AUTOSAR XML (schema 4-2-2)
package /UAES/ASW
  swc implementation Implementation: programming-language=C, sw-version=1.214.1, used-code-generator=Embedded Coder 7.1 (R2018b) 24-May-2018, vendor-id=0, behavior=InternalBehavior
    code-descriptors:
      code Code
        artifact-descriptors:
          short-label=Win_ComCnvRx_c, category=SWSRC
          short-label=Win_ComCnvRx_h, category=SWHDR
          short-label=rtwtypes_h, category=SWHDR
    resource consumption RsrcCons_Win_ComCnvRx
package /UAES/ASW/SwComponentTypes
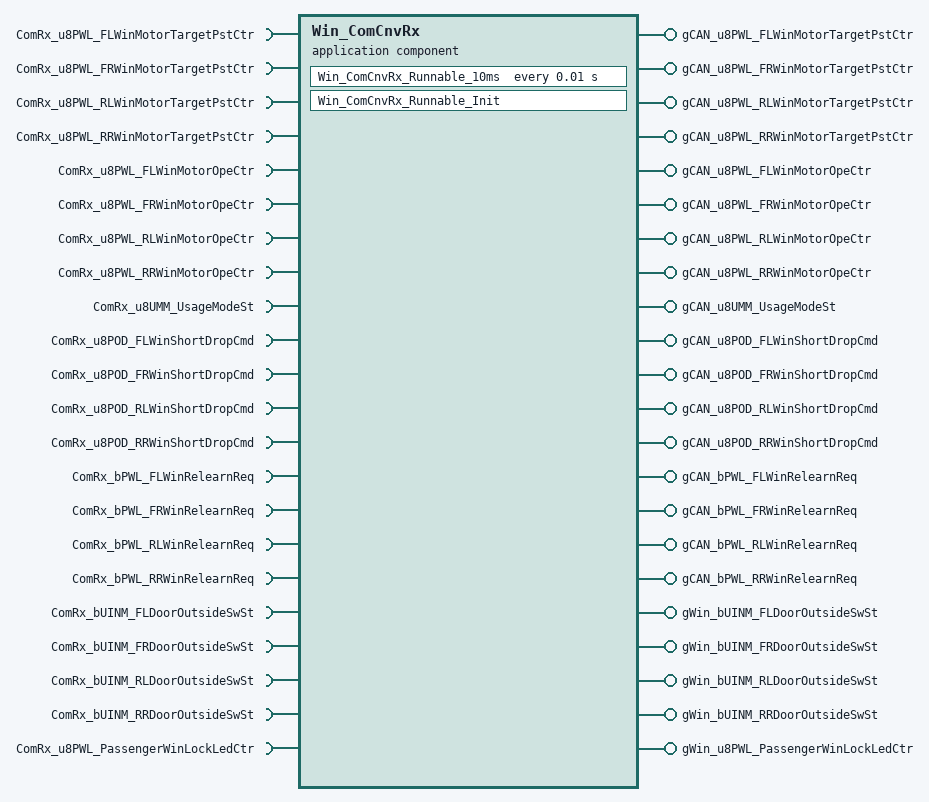
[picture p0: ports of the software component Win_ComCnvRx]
  application sw component type Win_ComCnvRx
    22 x require port:
      ComRx_u8PWL_FLWinMotorTargetPstCtr: nonqueued-receiver-com-spec{data-element=ComRx_u8PWL_FLWinMotorTargetPstCtr/Val, init-value=0}, required-interface=ComRx_u8PWL_FLWinMotorTargetPstCtr
      ComRx_u8PWL_FRWinMotorTargetPstCtr: nonqueued-receiver-com-spec{data-element=ComRx_u8PWL_FRWinMotorTargetPstCtr/Val, init-value=0}, required-interface=ComRx_u8PWL_FRWinMotorTargetPstCtr
      ComRx_u8PWL_RLWinMotorTargetPstCtr: nonqueued-receiver-com-spec{data-element=ComRx_u8PWL_RLWinMotorTargetPstCtr/Val, init-value=0}, required-interface=ComRx_u8PWL_RLWinMotorTargetPstCtr
      ComRx_u8PWL_RRWinMotorTargetPstCtr: nonqueued-receiver-com-spec{data-element=ComRx_u8PWL_RRWinMotorTargetPstCtr/Val, init-value=0}, required-interface=ComRx_u8PWL_RRWinMotorTargetPstCtr
      ComRx_u8PWL_FLWinMotorOpeCtr: nonqueued-receiver-com-spec{data-element=ComRx_u8PWL_FLWinMotorOpeCtr/Val, init-value=0}, required-interface=ComRx_u8PWL_FLWinMotorOpeCtr
      ComRx_u8PWL_FRWinMotorOpeCtr: nonqueued-receiver-com-spec{data-element=ComRx_u8PWL_FRWinMotorOpeCtr/Val, init-value=0}, required-interface=ComRx_u8PWL_FRWinMotorOpeCtr
      ComRx_u8PWL_RLWinMotorOpeCtr: nonqueued-receiver-com-spec{data-element=ComRx_u8PWL_RLWinMotorOpeCtr/Val, init-value=0}, required-interface=ComRx_u8PWL_RLWinMotorOpeCtr
      ComRx_u8PWL_RRWinMotorOpeCtr: nonqueued-receiver-com-spec{data-element=ComRx_u8PWL_RRWinMotorOpeCtr/Val, init-value=0}, required-interface=ComRx_u8PWL_RRWinMotorOpeCtr
      ComRx_u8UMM_UsageModeSt: nonqueued-receiver-com-spec{data-element=ComRx_u8UMM_UsageModeSt/Val, init-value=0}, required-interface=ComRx_u8UMM_UsageModeSt
      ComRx_u8POD_FLWinShortDropCmd: nonqueued-receiver-com-spec{data-element=ComRx_u8POD_FLWinShortDropCmd/Val, init-value=0}, required-interface=ComRx_u8POD_FLWinShortDropCmd
      ComRx_u8POD_FRWinShortDropCmd: nonqueued-receiver-com-spec{data-element=ComRx_u8POD_FRWinShortDropCmd/Val, init-value=0}, required-interface=ComRx_u8POD_FRWinShortDropCmd
      ComRx_u8POD_RLWinShortDropCmd: nonqueued-receiver-com-spec{data-element=ComRx_u8POD_RLWinShortDropCmd/Val, init-value=0}, required-interface=ComRx_u8POD_RLWinShortDropCmd
      ComRx_u8POD_RRWinShortDropCmd: nonqueued-receiver-com-spec{data-element=ComRx_u8POD_RRWinShortDropCmd/Val, init-value=0}, required-interface=ComRx_u8POD_RRWinShortDropCmd
      ComRx_bPWL_FLWinRelearnReq: nonqueued-receiver-com-spec{data-element=ComRx_bPWL_FLWinRelearnReq/Val, init-value=0}, required-interface=ComRx_bPWL_FLWinRelearnReq
      ComRx_bPWL_FRWinRelearnReq: nonqueued-receiver-com-spec{data-element=ComRx_bPWL_FRWinRelearnReq/Val, init-value=0}, required-interface=ComRx_bPWL_FRWinRelearnReq
      ComRx_bPWL_RLWinRelearnReq: nonqueued-receiver-com-spec{data-element=ComRx_bPWL_RLWinRelearnReq/Val, init-value=0}, required-interface=ComRx_bPWL_RLWinRelearnReq
      ComRx_bPWL_RRWinRelearnReq: nonqueued-receiver-com-spec{data-element=ComRx_bPWL_RRWinRelearnReq/Val, init-value=0}, required-interface=ComRx_bPWL_RRWinRelearnReq
      ComRx_bUINM_FLDoorOutsideSwSt: nonqueued-receiver-com-spec{data-element=ComRx_bUINM_FLDoorOutsideSwSt/Val, init-value=0}, required-interface=ComRx_bUINM_FLDoorOutsideSwSt
      ComRx_bUINM_FRDoorOutsideSwSt: nonqueued-receiver-com-spec{data-element=ComRx_bUINM_FRDoorOutsideSwSt/Val, init-value=0}, required-interface=ComRx_bUINM_FRDoorOutsideSwSt
      ComRx_bUINM_RLDoorOutsideSwSt: nonqueued-receiver-com-spec{data-element=ComRx_bUINM_RLDoorOutsideSwSt/Val, init-value=0}, required-interface=ComRx_bUINM_RLDoorOutsideSwSt
      ComRx_bUINM_RRDoorOutsideSwSt: nonqueued-receiver-com-spec{data-element=ComRx_bUINM_RRDoorOutsideSwSt/Val, init-value=0}, required-interface=ComRx_bUINM_RRDoorOutsideSwSt
      ComRx_u8PWL_PassengerWinLockLedCtr: nonqueued-receiver-com-spec{data-element=ComRx_u8PWL_PassengerWinLockLedCtr/Val, init-value=0}, required-interface=ComRx_u8PWL_PassengerWinLockLedCtr
    22 x provide port:
      gCAN_u8PWL_FLWinMotorTargetPstCtr: nonqueued-sender-com-spec{data-element=gCAN_u8PWL_FLWinMotorTargetPstCtr/Val, init-value=0}, provided-interface=gCAN_u8PWL_FLWinMotorTargetPstCtr
      gCAN_u8PWL_FRWinMotorTargetPstCtr: nonqueued-sender-com-spec{data-element=gCAN_u8PWL_FRWinMotorTargetPstCtr/Val, init-value=0}, provided-interface=gCAN_u8PWL_FRWinMotorTargetPstCtr
      gCAN_u8PWL_RLWinMotorTargetPstCtr: nonqueued-sender-com-spec{data-element=gCAN_u8PWL_RLWinMotorTargetPstCtr/Val, init-value=0}, provided-interface=gCAN_u8PWL_RLWinMotorTargetPstCtr
      gCAN_u8PWL_RRWinMotorTargetPstCtr: nonqueued-sender-com-spec{data-element=gCAN_u8PWL_RRWinMotorTargetPstCtr/Val, init-value=0}, provided-interface=gCAN_u8PWL_RRWinMotorTargetPstCtr
      gCAN_u8PWL_FLWinMotorOpeCtr: nonqueued-sender-com-spec{data-element=gCAN_u8PWL_FLWinMotorOpeCtr/Val, init-value=0}, provided-interface=gCAN_u8PWL_FLWinMotorOpeCtr
      gCAN_u8PWL_FRWinMotorOpeCtr: nonqueued-sender-com-spec{data-element=gCAN_u8PWL_FRWinMotorOpeCtr/Val, init-value=0}, provided-interface=gCAN_u8PWL_FRWinMotorOpeCtr
      gCAN_u8PWL_RLWinMotorOpeCtr: nonqueued-sender-com-spec{data-element=gCAN_u8PWL_RLWinMotorOpeCtr/Val, init-value=0}, provided-interface=gCAN_u8PWL_RLWinMotorOpeCtr
      gCAN_u8PWL_RRWinMotorOpeCtr: nonqueued-sender-com-spec{data-element=gCAN_u8PWL_RRWinMotorOpeCtr/Val, init-value=0}, provided-interface=gCAN_u8PWL_RRWinMotorOpeCtr
      gCAN_u8UMM_UsageModeSt: nonqueued-sender-com-spec{data-element=gCAN_u8UMM_UsageModeSt/Val, init-value=0}, provided-interface=gCAN_u8UMM_UsageModeSt
      gCAN_u8POD_FLWinShortDropCmd: nonqueued-sender-com-spec{data-element=gCAN_u8POD_FLWinShortDropCmd/Val, init-value=0}, provided-interface=gCAN_u8POD_FLWinShortDropCmd
      gCAN_u8POD_FRWinShortDropCmd: nonqueued-sender-com-spec{data-element=gCAN_u8POD_FRWinShortDropCmd/Val, init-value=0}, provided-interface=gCAN_u8POD_FRWinShortDropCmd
      gCAN_u8POD_RLWinShortDropCmd: nonqueued-sender-com-spec{data-element=gCAN_u8POD_RLWinShortDropCmd/Val, init-value=0}, provided-interface=gCAN_u8POD_RLWinShortDropCmd
      gCAN_u8POD_RRWinShortDropCmd: nonqueued-sender-com-spec{data-element=gCAN_u8POD_RRWinShortDropCmd/Val, init-value=0}, provided-interface=gCAN_u8POD_RRWinShortDropCmd
      gCAN_bPWL_FLWinRelearnReq: nonqueued-sender-com-spec{data-element=gCAN_bPWL_FLWinRelearnReq/Val, init-value=0}, provided-interface=gCAN_bPWL_FLWinRelearnReq
      gCAN_bPWL_FRWinRelearnReq: nonqueued-sender-com-spec{data-element=gCAN_bPWL_FRWinRelearnReq/Val, init-value=0}, provided-interface=gCAN_bPWL_FRWinRelearnReq
      gCAN_bPWL_RLWinRelearnReq: nonqueued-sender-com-spec{data-element=gCAN_bPWL_RLWinRelearnReq/Val, init-value=0}, provided-interface=gCAN_bPWL_RLWinRelearnReq
      gCAN_bPWL_RRWinRelearnReq: nonqueued-sender-com-spec{data-element=gCAN_bPWL_RRWinRelearnReq/Val, init-value=0}, provided-interface=gCAN_bPWL_RRWinRelearnReq
      gWin_bUINM_FLDoorOutsideSwSt: nonqueued-sender-com-spec{data-element=gWin_bUINM_FLDoorOutsideSwSt/Val, init-value=0}, provided-interface=gWin_bUINM_FLDoorOutsideSwSt
      gWin_bUINM_FRDoorOutsideSwSt: nonqueued-sender-com-spec{data-element=gWin_bUINM_FRDoorOutsideSwSt/Val, init-value=0}, provided-interface=gWin_bUINM_FRDoorOutsideSwSt
      gWin_bUINM_RLDoorOutsideSwSt: nonqueued-sender-com-spec{data-element=gWin_bUINM_RLDoorOutsideSwSt/Val, init-value=0}, provided-interface=gWin_bUINM_RLDoorOutsideSwSt
      gWin_bUINM_RRDoorOutsideSwSt: nonqueued-sender-com-spec{data-element=gWin_bUINM_RRDoorOutsideSwSt/Val, init-value=0}, provided-interface=gWin_bUINM_RRDoorOutsideSwSt
      gWin_u8PWL_PassengerWinLockLedCtr: nonqueued-sender-com-spec{data-element=gWin_u8PWL_PassengerWinLockLedCtr/Val, init-value=0}, provided-interface=gWin_u8PWL_PassengerWinLockLedCtr
    behavior InternalBehavior: handle-termination-and-restart=NO-SUPPORT
      init event Win_ComCnvRx_InitEvent: start-on-event=Win_ComCnvRx_Runnable_Init
      timing event TMT_Win_ComCnvRx_Runnable_10ms: start-on-event=Win_ComCnvRx_Runnable_10ms, period=0.01
      runnable Win_ComCnvRx_Runnable_Init
      runnable Win_ComCnvRx_Runnable_10ms
        data-receive-point-by-arguments:
          22 x access:
            IN_ComRx_bPWL_FLWinRelearnReq_Val: accessed-variable=ComRx_bPWL_FLWinRelearnReq.Val
            IN_ComRx_bPWL_FRWinRelearnReq_Val: accessed-variable=ComRx_bPWL_FRWinRelearnReq.Val
            IN_ComRx_bPWL_RLWinRelearnReq_Val: accessed-variable=ComRx_bPWL_RLWinRelearnReq.Val
            IN_ComRx_bPWL_RRWinRelearnReq_Val: accessed-variable=ComRx_bPWL_RRWinRelearnReq.Val
            IN_ComRx_bUINM_FLDoorOutsideSwSt_Val: accessed-variable=ComRx_bUINM_FLDoorOutsideSwSt.Val
            IN_ComRx_bUINM_FRDoorOutsideSwSt_Val: accessed-variable=ComRx_bUINM_FRDoorOutsideSwSt.Val
            IN_ComRx_bUINM_RLDoorOutsideSwSt_Val: accessed-variable=ComRx_bUINM_RLDoorOutsideSwSt.Val
            IN_ComRx_bUINM_RRDoorOutsideSwSt_Val: accessed-variable=ComRx_bUINM_RRDoorOutsideSwSt.Val
            IN_ComRx_u8POD_FLWinShortDropCmd_Val: accessed-variable=ComRx_u8POD_FLWinShortDropCmd.Val
            IN_ComRx_u8POD_FRWinShortDropCmd_Val: accessed-variable=ComRx_u8POD_FRWinShortDropCmd.Val
            IN_ComRx_u8POD_RLWinShortDropCmd_Val: accessed-variable=ComRx_u8POD_RLWinShortDropCmd.Val
            IN_ComRx_u8POD_RRWinShortDropCmd_Val: accessed-variable=ComRx_u8POD_RRWinShortDropCmd.Val
            IN_ComRx_u8PWL_FLWinMotorOpeCtr_Val: accessed-variable=ComRx_u8PWL_FLWinMotorOpeCtr.Val
            IN_ComRx_u8PWL_FLWinMotorTargetPstCtr_Val: accessed-variable=ComRx_u8PWL_FLWinMotorTargetPstCtr.Val
            IN_ComRx_u8PWL_FRWinMotorOpeCtr_Val: accessed-variable=ComRx_u8PWL_FRWinMotorOpeCtr.Val
            IN_ComRx_u8PWL_FRWinMotorTargetPstCtr_Val: accessed-variable=ComRx_u8PWL_FRWinMotorTargetPstCtr.Val
            IN_ComRx_u8PWL_PassengerWinLockLedCtr_Val: accessed-variable=ComRx_u8PWL_PassengerWinLockLedCtr.Val
            IN_ComRx_u8PWL_RLWinMotorOpeCtr_Val: accessed-variable=ComRx_u8PWL_RLWinMotorOpeCtr.Val
            IN_ComRx_u8PWL_RLWinMotorTargetPstCtr_Val: accessed-variable=ComRx_u8PWL_RLWinMotorTargetPstCtr.Val
            IN_ComRx_u8PWL_RRWinMotorOpeCtr_Val: accessed-variable=ComRx_u8PWL_RRWinMotorOpeCtr.Val
            IN_ComRx_u8PWL_RRWinMotorTargetPstCtr_Val: accessed-variable=ComRx_u8PWL_RRWinMotorTargetPstCtr.Val
            IN_ComRx_u8UMM_UsageModeSt_Val: accessed-variable=ComRx_u8UMM_UsageModeSt.Val
        data-send-points:
          22 x access:
            OUT_gCAN_u8PWL_FLWinMotorTargetPstCtr_Val: accessed-variable=gCAN_u8PWL_FLWinMotorTargetPstCtr.Val
            OUT_gCAN_u8PWL_FRWinMotorTargetPstCtr_Val: accessed-variable=gCAN_u8PWL_FRWinMotorTargetPstCtr.Val
            OUT_gCAN_u8PWL_RLWinMotorTargetPstCtr_Val: accessed-variable=gCAN_u8PWL_RLWinMotorTargetPstCtr.Val
            OUT_gCAN_u8PWL_RRWinMotorTargetPstCtr_Val: accessed-variable=gCAN_u8PWL_RRWinMotorTargetPstCtr.Val
            OUT_gCAN_u8PWL_FLWinMotorOpeCtr_Val: accessed-variable=gCAN_u8PWL_FLWinMotorOpeCtr.Val
            OUT_gCAN_u8PWL_FRWinMotorOpeCtr_Val: accessed-variable=gCAN_u8PWL_FRWinMotorOpeCtr.Val
            OUT_gCAN_u8PWL_RLWinMotorOpeCtr_Val: accessed-variable=gCAN_u8PWL_RLWinMotorOpeCtr.Val
            OUT_gCAN_u8PWL_RRWinMotorOpeCtr_Val: accessed-variable=gCAN_u8PWL_RRWinMotorOpeCtr.Val
            OUT_gCAN_u8UMM_UsageModeSt_Val: accessed-variable=gCAN_u8UMM_UsageModeSt.Val
            OUT_gCAN_u8POD_FLWinShortDropCmd_Val: accessed-variable=gCAN_u8POD_FLWinShortDropCmd.Val
            OUT_gCAN_u8POD_FRWinShortDropCmd_Val: accessed-variable=gCAN_u8POD_FRWinShortDropCmd.Val
            OUT_gCAN_u8POD_RLWinShortDropCmd_Val: accessed-variable=gCAN_u8POD_RLWinShortDropCmd.Val
            OUT_gCAN_u8POD_RRWinShortDropCmd_Val: accessed-variable=gCAN_u8POD_RRWinShortDropCmd.Val
            OUT_gCAN_bPWL_FLWinRelearnReq_Val: accessed-variable=gCAN_bPWL_FLWinRelearnReq.Val
            OUT_gCAN_bPWL_FRWinRelearnReq_Val: accessed-variable=gCAN_bPWL_FRWinRelearnReq.Val
            OUT_gCAN_bPWL_RLWinRelearnReq_Val: accessed-variable=gCAN_bPWL_RLWinRelearnReq.Val
            OUT_gCAN_bPWL_RRWinRelearnReq_Val: accessed-variable=gCAN_bPWL_RRWinRelearnReq.Val
            OUT_gWin_bUINM_FLDoorOutsideSwSt_Val: accessed-variable=gWin_bUINM_FLDoorOutsideSwSt.Val
            OUT_gWin_bUINM_FRDoorOutsideSwSt_Val: accessed-variable=gWin_bUINM_FRDoorOutsideSwSt.Val
            OUT_gWin_bUINM_RLDoorOutsideSwSt_Val: accessed-variable=gWin_bUINM_RLDoorOutsideSwSt.Val
            OUT_gWin_bUINM_RRDoorOutsideSwSt_Val: accessed-variable=gWin_bUINM_RRDoorOutsideSwSt.Val
            OUT_gWin_u8PWL_PassengerWinLockLedCtr_Val: accessed-variable=gWin_u8PWL_PassengerWinLockLedCtr.Val
package /UAES/ASW/PortInterfaces
  44 x sender receiver interface:
    ComRx_u8PWL_FLWinMotorTargetPstCtr
      data Val: category=VALUE, sw-calibration-access=READ-ONLY, type=uint8
    ComRx_u8PWL_FRWinMotorTargetPstCtr
      data Val: category=VALUE, sw-calibration-access=READ-ONLY, type=uint8
    ComRx_u8PWL_RLWinMotorTargetPstCtr
      data Val: category=VALUE, sw-calibration-access=READ-ONLY, type=uint8
    ComRx_u8PWL_RRWinMotorTargetPstCtr
      data Val: category=VALUE, sw-calibration-access=READ-ONLY, type=uint8
    ComRx_u8PWL_FLWinMotorOpeCtr
      data Val: category=VALUE, sw-calibration-access=READ-ONLY, type=uint8
    ComRx_u8PWL_FRWinMotorOpeCtr
      data Val: category=VALUE, sw-calibration-access=READ-ONLY, type=uint8
    ComRx_u8PWL_RLWinMotorOpeCtr
      data Val: category=VALUE, sw-calibration-access=READ-ONLY, type=uint8
    ComRx_u8PWL_RRWinMotorOpeCtr
      data Val: category=VALUE, sw-calibration-access=READ-ONLY, type=uint8
    ComRx_u8UMM_UsageModeSt
      data Val: category=VALUE, sw-calibration-access=READ-ONLY, type=uint8
    ComRx_u8POD_FLWinShortDropCmd
      data Val: category=VALUE, sw-calibration-access=READ-ONLY, type=uint8
    ComRx_u8POD_FRWinShortDropCmd
      data Val: category=VALUE, sw-calibration-access=READ-ONLY, type=uint8
    ComRx_u8POD_RLWinShortDropCmd
      data Val: category=VALUE, sw-calibration-access=READ-ONLY, type=uint8
    ComRx_u8POD_RRWinShortDropCmd
      data Val: category=VALUE, sw-calibration-access=READ-ONLY, type=uint8
    ComRx_bPWL_FLWinRelearnReq
      data Val: category=VALUE, sw-calibration-access=READ-ONLY, type=boolean
    ComRx_bPWL_FRWinRelearnReq
      data Val: category=VALUE, sw-calibration-access=READ-ONLY, type=boolean
    ComRx_bPWL_RLWinRelearnReq
      data Val: category=VALUE, sw-calibration-access=READ-ONLY, type=boolean
    ComRx_bPWL_RRWinRelearnReq
      data Val: category=VALUE, sw-calibration-access=READ-ONLY, type=boolean
    ComRx_bUINM_FLDoorOutsideSwSt
      data Val: category=VALUE, sw-calibration-access=READ-ONLY, type=boolean
    ComRx_bUINM_FRDoorOutsideSwSt
      data Val: category=VALUE, sw-calibration-access=READ-ONLY, type=boolean
    ComRx_bUINM_RLDoorOutsideSwSt
      data Val: category=VALUE, sw-calibration-access=READ-ONLY, type=boolean
    ComRx_bUINM_RRDoorOutsideSwSt
      data Val: category=VALUE, sw-calibration-access=READ-ONLY, type=boolean
    ComRx_u8PWL_PassengerWinLockLedCtr
      data Val: category=VALUE, sw-calibration-access=READ-ONLY, type=uint8
    gCAN_u8PWL_FLWinMotorTargetPstCtr
      data Val: category=VALUE, sw-calibration-access=READ-ONLY, type=uint8
    gCAN_u8PWL_FRWinMotorTargetPstCtr
      data Val: category=VALUE, sw-calibration-access=READ-ONLY, type=uint8
    gCAN_u8PWL_RLWinMotorTargetPstCtr
      data Val: category=VALUE, sw-calibration-access=READ-ONLY, type=uint8
    gCAN_u8PWL_RRWinMotorTargetPstCtr
      data Val: category=VALUE, sw-calibration-access=READ-ONLY, type=uint8
    gCAN_u8PWL_FLWinMotorOpeCtr
      data Val: category=VALUE, sw-calibration-access=READ-ONLY, type=uint8
    gCAN_u8PWL_FRWinMotorOpeCtr
      data Val: category=VALUE, sw-calibration-access=READ-ONLY, type=uint8
    gCAN_u8PWL_RLWinMotorOpeCtr
      data Val: category=VALUE, sw-calibration-access=READ-ONLY, type=uint8
    gCAN_u8PWL_RRWinMotorOpeCtr
      data Val: category=VALUE, sw-calibration-access=READ-ONLY, type=uint8
    gCAN_u8UMM_UsageModeSt
      data Val: category=VALUE, sw-calibration-access=READ-ONLY, type=uint8
    gCAN_u8POD_FLWinShortDropCmd
      data Val: category=VALUE, sw-calibration-access=READ-ONLY, type=uint8
    gCAN_u8POD_FRWinShortDropCmd
      data Val: category=VALUE, sw-calibration-access=READ-ONLY, type=uint8
    gCAN_u8POD_RLWinShortDropCmd
      data Val: category=VALUE, sw-calibration-access=READ-ONLY, type=uint8
    gCAN_u8POD_RRWinShortDropCmd
      data Val: category=VALUE, sw-calibration-access=READ-ONLY, type=uint8
    gCAN_bPWL_FLWinRelearnReq
      data Val: category=VALUE, sw-calibration-access=READ-ONLY, type=boolean
    gCAN_bPWL_FRWinRelearnReq
      data Val: category=VALUE, sw-calibration-access=READ-ONLY, type=boolean
    gCAN_bPWL_RLWinRelearnReq
      data Val: category=VALUE, sw-calibration-access=READ-ONLY, type=boolean
    gCAN_bPWL_RRWinRelearnReq
      data Val: category=VALUE, sw-calibration-access=READ-ONLY, type=boolean
    gWin_bUINM_FLDoorOutsideSwSt
      data Val: category=VALUE, sw-calibration-access=READ-ONLY, type=boolean
    gWin_bUINM_FRDoorOutsideSwSt
      data Val: category=VALUE, sw-calibration-access=READ-ONLY, type=boolean
    gWin_bUINM_RLDoorOutsideSwSt
      data Val: category=VALUE, sw-calibration-access=READ-ONLY, type=boolean
    gWin_bUINM_RRDoorOutsideSwSt
      data Val: category=VALUE, sw-calibration-access=READ-ONLY, type=boolean
    gWin_u8PWL_PassengerWinLockLedCtr
      data Val: category=VALUE, sw-calibration-access=READ-ONLY, type=uint8
